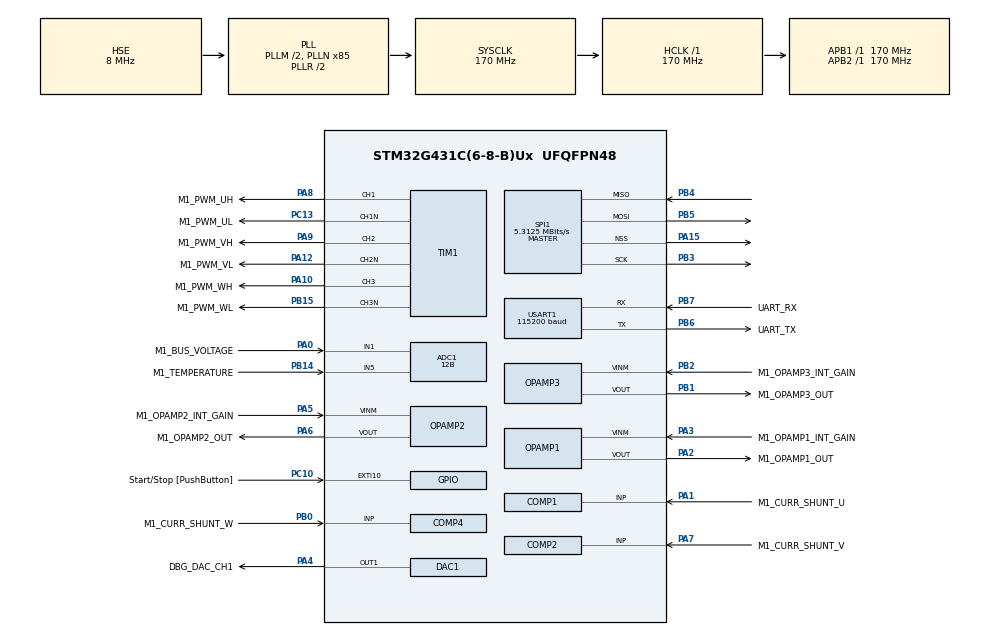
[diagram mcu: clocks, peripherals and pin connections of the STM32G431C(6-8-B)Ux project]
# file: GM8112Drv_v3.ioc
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MotorControl.BEMF_CONSISTENCY_TOL=64
MotorControl.R_BRAKE_SWITCH_OFF_THRES_V=22
MotorControl.PID_FLUX_KI_DEFAULT=3865
MotorControl.LOW_SIDE_BRAKE_STATE=false
ADC1.LowPowerAutoWait=DISABLE
MotorControl.PHASE_VL_GPIO_PORT=GPIOA
MotorControl.IPs=CORDIC,NVIC,RCC,SYS,MotorControl,TIM1,COMP1,COMP2,COMP4,OPAMP1,OPAMP2,OPAMP3,ADC1,ADC2,TIM2,DAC1,USART1
MotorControl.OCP_OUTPUT_MODE=INT_MODE
PC10.GPIO_PuPd=GPIO_NOPULL
ADC1.InjectedOffsetNumber-2\#ChannelInjectedConversion=ADC_OFFSET_NONE
MotorControl.PHASE_VH_POLARITY=H_ACTIVE_HIGH
MotorControl.THREE_SHUNT_INDEPENDENT_RESOURCES=true
MotorControl.PHASE_WL_GPIO_PIN=LL_GPIO_PIN_15
PA10.GPIO_PuPd=GPIO_PULLDOWN
MotorControl.ENCODER_PPR=400
ADC2.InjectedChannel-2\#ChannelInjectedConversion=ADC_CHANNEL_VOPAMP3_ADC2
MotorControl.OV_VOLTAGE_PROT_ENABLING=true
MotorControl.OPEN_LOOP_SPEED_RAMP_DURATION_MS=1000
MotorControl.OCPB_OUTPUT_GPIO_PORT=GPIOA
MotorControl.ANGC={0,0,0,0,0,0,0,0}
MotorControl.SINGLEDRIVE=true
MotorControl.HFI_HP_ID_1_COEFF=-1.741737
MotorControl.USART_REMAPPING=NO_REMAP_USART1
MotorControl.EMERGENCY_STOP_GPIO_PORT=GPIOA
MotorControl.OCPC_OUTPUT_MODE=INT_MODE
MotorControl.OPEN_LOOP_VOLTAGE_d=6000
COMP2.Output=COMP_OUTPUT_TIM1BKIN2
MotorControl.OCPB_OUTPUT_MODE=INT_MODE
MotorControl.OCPA_OUTPUT_MODE=INT_MODE
MotorControl.OCPC_INVERTINGINPUT_MODE=INT_MODE
MotorControl.HFI_LP_ID_1_COEFF=0.052094
MotorControl.OVP_FILTER=COMP_Mode_HighSpeed
MotorControl.DEFAULT_DAC_MOTOR=0
MotorControl.TF_KDDIV=8192
MotorControl.H3_GPIO_PORT=GPIOB
TIM1.Pulse-PWM\ Generation5\ No\ Output=(((PWM_PERIOD_CYCLES) / 2) + 1)
SPI1.Direction=SPI_DIRECTION_2LINES
RCC.APB2TimFreq_Value=170000000
MotorControl.HFI_DC_2_COEFF=0.00146
PB6.Signal=USART1_TX
SPI1.CalculateBaudRate=5.3125 MBits/s
MotorControl.HFI_NOTCH_IQD_4_COEFF=-0.871066
MotorControl.OCP_NONINVERTINGINPUT_GPIO_PIN=LL_GPIO_PIN_7
ADC2.EOCSelection=ADC_EOC_SINGLE_CONV
MotorControl.FINAL_I_ALIGNMENT=816
MotorControl.OVP_OUTPUT_GPIO_PIN=LL_GPIO_PIN_2
MotorControl.ENCODER_AVAILABLE=true
MotorControl.OPAMP1_INVERTINGINPUT_GPIO_PORT=GPIOA
NVIC.EXTI15_10_IRQn=true\:3\:0\:false\:true\:false\:6\:true\:true
MotorControl.HFI_RESTARTTIMESEC=0.1
OPAMP2.PgaGain=OPAMP_PGA_GAIN_16_OR_MINUS_15
MotorControl.HALL_ICx_FILTER=221
PB3.Mode=Full_Duplex_Master
ADC1.ScanConvMode=ADC_SCAN_ENABLE
MotorControl.ENC_MEAS_ERRORS_BEFORE_FAULTS=3
TIM1.LockLevel=TIM_LOCKLEVEL_1
MotorControl.HFI_WAITTRACK=20
MotorControl.OPAMP3_NONINVERTINGINPUT_PHB_GPIO_PORT=GPIOB
RCC.ADC12Freq_Value=42500000
MotorControl.ADC_AHBPERIPH=RCC_AHBPeriph_ADC12
TIM1.Break2Polarity=TIM_BREAK2POLARITY_HIGH
MotorControl.PID_TORQUE_KI_DEFAULT=3865
PB14.Mode=IN5-Single-Ended
MotorControl.H2_GPIO_PIN=LL_GPIO_PIN_7
PB1.GPIO_Label=M1_OPAMP3_OUT
TIM1.DeadTime=((DEAD_TIME_COUNTS) / 2)
MotorControl.DAC_TIMER_CH1_GPIO_PIN=LL_GPIO_PIN_4
SPI1.DataSize=SPI_DATASIZE_16BIT
TIM1.OCMode_PWM-PWM\ Generation1\ CH1\ CH1N=TIM_OCMODE_PWM1
MotorControl.AMPLIFICATION_GAIN=9.14
MotorControl.PWBDID=10015
PA8.Signal=S_TIM1_CH1
ADC1.InjectedConvMode=None
MotorControl.PWM_TIMER_REMAPPING=PWM_PARTIAL_REMAP
MotorControl.HFI_WAITSYNCH=20
PA0.Signal=ADC1_IN1
MotorControl.OPAMP3_NONINVERTINGINPUT_PHC_GPIO_PIN=LL_GPIO_PIN_0
MotorControl.OCPB_SELECTION=COMP2
ExtraMW.MotorControl.Template=templates
MotorControl.CORD_MEAS_ERRORS_BEFORE_FAULTS=3
MotorControl.OV_TEMPERATURE_THRESHOLD_C=110
Mcu.Package=UFQFPN48
PB1.Signal=SharedAnalog_PB1
ADC1.InjectedChannel-2\#ChannelInjectedConversion=ADC_CHANNEL_12
MotorControl.OCPB_INVERTINGINPUT_MODE=INT_MODE
MotorControl.OPAMP2_NONINVERTINGINPUT_PHC_GPIO_PIN=LL_GPIO_PIN_7
TIM1.OCMode_PWM-PWM\ Generation3\ CH3\ CH3N=TIM_OCMODE_PWM1
PA10.Signal=S_TIM1_CH3
MotorControl.HIGH_SIDE_BRAKE_STATE=false
MotorControl.DRIVES_NUMBER_SELECTION=SINGLEDRIVE
VP_COMP2_VS_VREFINT14.Mode=VREFINT_14
MotorControl.USART_SELECTION=USE_USART1
MotorControl.OPAMP2_SELECTION=OPAMP2
MotorControl.PHASE4_DURATION=3484
RCC.APB1TimFreq_Value=170000000
ADC1.InjectedOffsetNumber-1\#ChannelInjectedConversion=ADC_OFFSET_NONE
MotorControl.HFI_SPD_BUFFER_DEPTH_01HZ=64
ADC2.ExternalTrigInjecConvEdge=ADC_EXTERNALTRIGINJECCONV_EDGE_RISING
MotorControl.USE_3OPAMPS=true
MotorControl.OPAMP_INVERTINGINPUT=OPAMP1_InvertingInput_PA3
ADC1.InjectedChannel-1\#ChannelInjectedConversion=ADC_CHANNEL_3
MotorControl.VARIANCE_THRESHOLD=0.1
ADC2.EnableAnalogWatchDog1=false
MotorControl.SPD_DIFFERENTIAL_TERM_ENABLING=false
ADC2.EnableAnalogWatchDog2=false
PA4.GPIO_Label=DBG_DAC_CH1
PA8.GPIO_Speed=GPIO_SPEED_FREQ_HIGH
ADC1.EOCSelection=ADC_EOC_SINGLE_CONV
ADC2.EnableAnalogWatchDog3=false
MotorControl.PID_SPEED_KI_DEFAULT=2693
MotorControl.SP_KIDIV=8192
PF1-OSC_OUT.Signal=RCC_OSC_OUT
RCC.HSI48_VALUE=48000000
ADC2.ScanConvMode=ADC_SCAN_ENABLE
MotorControl.OPAMP1_OUT_GPIO_PORT=GPIOA
PA5.Mode=PGA Connected-INVERTINGINPUT_IO0_BIAS
MotorControl.HFI_NS_MIN_SAT_DIFF=0
MotorControl.HFI_IDH_DELAY=32400
MotorControl.PHASE_W_GPIO_PORT=GPIOB
MotorControl.BKIN_MODE=NONE
MotorControl.OVP_INVERTINGINPUT_GPIO_PORT=GPIOA
MotorControl.PHASE_CURRENTS_GPIO_PIN=LL_GPIO_PIN_0
TIM1.CounterMode=TIM_COUNTERMODE_CENTERALIGNED1
PC13.Signal=TIM1_CH1N
MotorControl.WB_to_Mx_version=1.1.0
PB6.GPIO_PuPd=GPIO_NOPULL
MotorControl.TEMP_FDBK_ADC=ADC1
MotorControl.OPEN_LOOP_SPEED_RPM=100
MotorControl.CORD_FIFO_DEPTH_01HZ=64
MotorControl.REGULATION_EXECUTION_RATE=1
MotorControl.INRUSH_CURRLIMIT_CHANGE_AFTER_MS=1000
MotorControl.OPAMP2_NONINVERTINGINPUT_PHC_GPIO_PORT=GPIOA
MotorControl.BKIN2_FILTER=3
PA3.Mode=PGA Connected-INVERTINGINPUT_IO0_BIAS
TIM1.AutoReloadPreload=TIM_AUTORELOAD_PRELOAD_DISABLE
MotorControl.HFI_DC_3_COEFF=1.889033
MotorControl.PHASE_CURRENTS_CHANNEL=ADC_CHANNEL_9
TIM1.Channel-PWM\ Generation2\ CH2\ CH2N=TIM_CHANNEL_2
PA8.GPIO_Label=M1_PWM_UH
MotorControl.HIGH_SIDE_IDLE_STATE=false
SH.SharedAnalog_PA7.1=OPAMP2_VINP,PGA Connected-INVERTINGINPUT_IO0_BIAS
MotorControl.HFI_FREQUENCY=400
MotorControl.SP_KPDIV=1024
MotorControl.OCPA_INVERTINGINPUT_GPIO_PORT=GPIOA
SH.COMP_DAC11_group.0=DAC1_OUT1,DAC_OUT1
MotorControl.OPAMP2_NONINVERTINGINPUT_PHB_GPIO_PORT=GPIOA
MotorControl.OVP_SELECTION=COMP2
SH.SharedAnalog_PA7.0=COMP2_INP,INP
MotorControl.CTRBDID=10015
MotorControl.POSITION_CTRL_KD_GAIN=1000
MotorControl.PHASE_UH_GPIO_PIN=LL_GPIO_PIN_8
MotorControl.BKIN2_MODE=INT_MODE
PB14.Signal=ADC1_IN5
PA5.Signal=OPAMP2_VINM
MotorControl.INRUSH_CURRLIMIT_GPIO_PIN=LL_GPIO_PIN_4
MotorControl.NOMINAL_BUS_VOLTAGE_V=22
NVIC.TIM1_BRK_TIM15_IRQn=true\:4\:1\:true\:true\:false\:1\:true\:true
MotorControl.HFI_NOTCH_IQD_0_COEFF=0.935533
MotorControl.OCPC_OUTPUT_GPIO_PIN=LL_GPIO_PIN_1
MotorControl.DEBUG_DAC_CH2=false
MotorControl.DEBUG_DAC_CH1=true
MotorControl.LCD_MODE=LCD_FULL
TIM1.TIM_MasterOutputTrigger=TIM_TRGO_OC4REF
VP_COMP4_VS_VREFINT14.Mode=VREFINT_14
MotorControl.OCPC_NONINVERTINGINPUT=COMP4_NonInvertingInput_PB0
PB15.GPIO_Label=M1_PWM_WL
SPI1.Mode=SPI_MODE_MASTER
PA1.GPIO_Label=M1_CURR_SHUNT_U
MotorControl.OPAMP_NONINVERTINGINPUT_GPIO_PIN=LL_GPIO_PIN_7
MotorControl.OCP_INVERTINGINPUT_GPIO_PORT=GPIOA
MotorControl.PHASE4_FINAL_SPEED_RPM=120
TIM1.Channel-PWM\ Generation4\ No\ Output=TIM_CHANNEL_4
MotorControl.OCPC_INVERTINGINPUT_GPIO_PIN=LL_GPIO_PIN_4
MotorControl.OPAMP_OUT_GPIO_PORT=GPIOA
ADC2.Resolution=ADC_RESOLUTION_12B
MotorControl.PHASE1_FINAL_SPEED_RPM=0
MotorControl.OCP_OUTPUTPOL=COMP_OutputPol_NonInverted
MotorControl.OCPB_OUTPUT=COMP_Output_TIM1BKIN2
MotorControl.HFI_NOTCH_IQD_3_COEFF=1.798584
ADC1.ExternalTrigConv=ADC_SOFTWARE_START
MotorControl.HFI_AMPLITUDE=25
ADC1.master=1
PA5.GPIO_Label=M1_OPAMP2_INT_GAIN
MotorControl.START_STOP_POLARITY_EDGE=GPIO_NOPULL
RCC.ADC12CLockSelection=RCC_ADC12CLKSOURCE_PLL
MotorControl.POSITION_CTRL_KDDIV=16
MotorControl.OCP_OUTPUT_GPIO_AF=GPIO_AF_2
MotorControl.OFST={0,0,0,0,0,0,0,0}
ProjectManager.HeapSize=0x200
ADC2.InjectedChannel-1\#ChannelInjectedConversion=ADC_CHANNEL_3
OPAMP1.SelfCalibration=Disable
MotorControl.START_STOP_BTN=true
NVIC.PriorityGroup=NVIC_PRIORITYGROUP_3
TIM1.SourceBRK2DigInput=TIM_BREAKINPUTSOURCE_DISABLE
VP_MotorControl_MC_ENABLED.Mode=Enabled
MotorControl.SW_OV_CURRENT_PROT_ENABLING=true
MotorControl.OCPB_INVERTINGINPUT=COMPX_InvertingInput_VREF_1_4
MotorControl.UD_VOLTAGE_THRESHOLD_V=8
Mcu.Family=STM32G4
MotorControl.PHASE3_FINAL_CURRENT=816
MotorControl.PHASE2_FINAL_SPEED_RPM=120
MotorControl.USART_RX_GPIO_PORT=GPIOB
MotorControl.HFI_DC_1_COEFF=0.002921
MotorControl.EMERGENCY2_STOP_GPIO_PORT=GPIOA
MotorControl.EMERGENCY2_STOP_GPIO_PIN=LL_GPIO_PIN_11
MotorControl.OPAMP3_INVERTINGINPUT_GPIO_PIN=LL_GPIO_PIN_2
ADC1.Overrun=ADC_OVR_DATA_PRESERVED
MotorControl.OCPB_INVERTINGINPUT_GPIO_PORT=GPIOA
ADC1.ContinuousConvMode=DISABLE
MotorControl.OPEN_LOOP_VF=false
USART1.BaudRate=115200
MotorControl.RTOS=NONE
MotorControl.PHASE_V_GPIO_PIN=LL_GPIO_PIN_6
PA0.GPIO_Label=M1_BUS_VOLTAGE
MotorControl.PHASE_VL_GPIO_PIN=LL_GPIO_PIN_12
MotorControl.HW_OV_CURRENT_PROT_BYPASS=false
MotorControl.H2_GPIO_PORT=GPIOB
MotorControl.PHASE_WH_POLARITY=H_ACTIVE_HIGH
TIM1.Pulse-PWM\ Generation1\ CH1=((PWM_PERIOD_CYCLES) / 4)
MotorControl.OVP_NONINVERTINGINPUT=COMP2_NonInvertingInput_PA7
MotorControl.OVP_OUTPUT_GPIO_AF=GPIO_AF_2
PB15.Signal=TIM1_CH3N
ADC2.DiscontinuousConvMode=DISABLE
MotorControl.DEFAULT_FLUX_COMPONENT=0
MotorControl.OCP_NONINVERTINGINPUT=COMP2_NonInvertingInput_PA7
MotorControl.OVERCURR_FEEDBACK_POLARITY=EMSTOP_ACTIVE_LOW
MotorControl.LOW_SIDE_IDLE_STATE=false
MotorControl.OCPC_OUTPUT_GPIO_AF=GPIO_AF_2
MotorControl.MAX_APPLICATION_SPEED=300
MotorControl.HFI_LP_ID_0_COEFF=0.026047
MotorControl.PHASE_UH_POLARITY=H_ACTIVE_HIGH
MotorControl.OCPC_SELECTION=COMP4
TIM1.Prescaler=((TIM_CLOCK_DIVIDER) - 1)
MotorControl.OCPC_OUTPUT_GPIO_PORT=GPIOB
MotorControl.VBUS_PARTITIONING_FACTOR=0.0963
MotorControl.OCPC_NONINVERTINGINPUT_GPIO_PORT=GPIOB
ADC1.Resolution=ADC_RESOLUTION_12B
MotorControl.OCPA_INVERTINGINPUT=COMPX_InvertingInput_VREF_1_4
ADC2.InjectedRank-1\#ChannelInjectedConversion=1
RCC.HSE_VALUE=8000000
MotorControl.OPAMP2_INVERTINGINPUT_GPIO_PORT=GPIOA
ADC2.master=1
ADC2.InjectedRank-2\#ChannelInjectedConversion=2
MotorControl.FEED_FORWARD_CURRENT_REG_ENABLING=false
MotorControl.PID_SPEED_KD_DEFAULT=0
PC10.GPIO_ModeDefaultEXTI=GPIO_MODE_IT_FALLING
MotorControl.HFI_LOCKFREQ=73
MotorControl.OCPA_SELECTION=COMP1
MotorControl.HFI_LP_ID_2_COEFF=0.026047
PA14.Mode=Serial_Wire
PB5.Mode=Full_Duplex_Master
MotorControl.OCPA_OUTPUT_GPIO_AF=GPIO_AF_2
VP_ADC2_OPAMP_INTERNAL3.Mode=IN-OPAMP3
PC13.GPIO_PuPd=GPIO_PULLDOWN
VP_SYS_VS_DBSignals.Mode=DisableDeadBatterySignals
MotorControl.OVP_OUTPUT_GPIO_PORT=GPIOA
PB7.Signal=USART1_RX
MotorControl.HALL_MEAS_ERRORS_BEFORE_FAULTS=3
MotorControl.OPAMP3_NONINVERTINGINPUT_PHC_GPIO_PORT=GPIOB
MotorControl.FW_VOLTAGE_REF=985
MotorControl.PID_FLUX_KD_DEFAULT=100
MotorControl.HFI_PID_KP_DEFAULT=800
MotorControl.VBUS_CHANNEL=ADC_CHANNEL_1
MotorControl.SERIAL_COM_MODE=COM_BIDIRECTIONAL
PB7.GPIO_Label=UART_RX
ADC2.InjectedSamplingTime-1\#ChannelInjectedConversion=ADC_SAMPLETIME_6CYCLES_5
MotorControl.OPAMP1_NONINVERTINGINPUT_PHB=OPAMP1_NonInvertingInput_PA1
MotorControl.PHASE_V_CURR_ADC=ADC2
PA6.Signal=SharedAnalog_PA6
MotorControl.OPAMP1_NONINVERTINGINPUT_PHA=OPAMP1_NonInvertingInput_PA1
MotorControl.PHASE_VH_GPIO_PIN=LL_GPIO_PIN_9
PB15.GPIO_PuPd=GPIO_PULLDOWN
TIM1.Pulse-PWM\ Generation2\ CH2=((PWM_PERIOD_CYCLES) / 4)
MotorControl.R_BRAKE_GPIO_PIN=LL_GPIO_PIN_5
MotorControl.OCPB_OUTPUT_GPIO_AF=GPIO_AF_2
MotorControl.HFI_NSDETPOINTSSKIP=10
PA15.Signal=SPI1_NSS
MotorControl.OPAMP_NONINVERTINGINPUT=OPAMP1_NonInvertingInput_PA7
MotorControl.PLL_KI_GAIN=29
PA10.GPIO_Speed=GPIO_SPEED_FREQ_HIGH
MotorControl.POLE_PAIR_NUM=21
MotorControl.PHASE1_FINAL_CURRENT=816
MotorControl.OPAMP2_OUT_GPIO_PORT=GPIOA
MotorControl.SP_KDDIV=16
TIM1.BreakState=TIM_BREAK_DISABLE
MotorControl.PHASE_V_CURR_CHANNEL=ADC_CHANNEL_3
MotorControl.HFI_HIFRAMPLSCAN=25
MotorControl.HFI_MAXANGLEDIFF=3640
MotorControl.SW_DEADTIME_NS=800
MotorControl.FW_KPDIV=32768
MotorControl.OCPA_INVERTINGINPUT_MODE=INT_MODE
ADC1.InjectedSamplingTime-1\#ChannelInjectedConversion=ADC_SAMPLETIME_6CYCLES_5
PF1-OSC_OUT.Mode=HSE-External-Oscillator
MotorControl.CUBE_MX_VER=5.6.1
MotorControl.SPEED_BAND_LOWER_LIMIT=15
PA12.GPIO_Speed=GPIO_SPEED_FREQ_HIGH
MotorControl.PWM_TIMER_SELECTION=PWM_TIM1
MotorControl.R_BRAKE_GPIO_PORT=GPIOD
PB4.Signal=SPI1_MISO
MotorControl.OVP_OUTPUT=COMP_Output_TIM1BKIN
PA3.Signal=OPAMP1_VINM
MotorControl.OCP_NONINVERTINGINPUT_GPIO_PORT=GPIOA
TIM1.SourceBRK2COMP2Polarity=TIM_BREAKINPUTSOURCE_POLARITY_HIGH
MotorControl.CLOCK_FREQUENCY=CPU_CLK_170_MHZ
MotorControl.POSITION_LOOP_FREQUENCY_HZ=1000
MotorControl.EXT_CLOCK_FREQUENCY=EXT_CLK_8_MHZ
MotorControl.PHASE_U_GPIO_PIN=LL_GPIO_PIN_2
TIM1.OCMode_PWM-PWM\ Generation4\ No\ Output=TIM_OCMODE_PWM2
MotorControl.HFI_MINIMUM_SPEED_RPM=402
ADC2.ExternalTrigInjecConv=ADC_EXTERNALTRIGINJEC_T1_CC4
TIM1.OffStateIDLEMode=TIM_OSSI_ENABLE
MotorControl.STO_FIFO_DEPTH_DPP=64
MotorControl.TRANSITION_DURATION=25
MotorControl.STO_FIFO_DEPTH_01HZ=64
MotorControl.OV_CURR_BYPASS_GPIO_PIN=LL_GPIO_PIN_5
MotorControl.CORD_VARIANCE_THRESHOLD=4
MotorControl.HFI_STEPANGLE=3640
MotorControl.OCP_OUTPUT_GPIO_PIN=LL_GPIO_PIN_2
MotorControl.HFI_LP_ID_4_COEFF=-0.598595
MotorControl.PHASE1_DURATION=1000
MotorControl.ENC_ICx_FILTER=128
ADC2.EnableRegularConversion=DISABLE
MotorControl.STO_HFI_RPM_TH=460
PA9.GPIO_PuPd=GPIO_PULLDOWN
PA12.GPIO_Label=M1_PWM_VL
MotorControl.PHASE_UL_GPIO_AF=GPIO_AF_4
MotorControl.GAIN1=-20371
MotorControl.GAIN2=17965
USART1.VirtualMode-Asynchronous=VM_ASYNC
PA13.Signal=SYS_JTMS-SWDIO
TIM1.Pulse-PWM\ Generation3\ CH3=((PWM_PERIOD_CYCLES) / 4)
VP_COMP1_VS_VREFINT14.Mode=VREFINT_14
SH.S_TIM1_CH1.0=TIM1_CH1,PWM Generation1 CH1 CH1N
MotorControl.PHASE5_FINAL_CURRENT=816
MotorControl.OCPA_NONINVERTINGINPUT=COMP1_NonInvertingInput_PA1
MotorControl.ENC_INVERT_SPEED=false
MotorControl.DEFAULT_CONTROL_MODE=STC_SPEED_MODE
ADC1.EnableAnalogWatchDog3=false
ADC1.EnableAnalogWatchDog2=false
ADC1.EnableAnalogWatchDog1=false
RCC.USBFreq_Value=170000000
MotorControl.PLL_KP_GAIN=372
PA1.Signal=SharedAnalog_PA1
MotorControl.OBS_MINIMUM_SPEED_RPM=90
MotorControl.HFI_NSMAXDETPOINTS=20
MotorControl.PHASE3_FINAL_SPEED_RPM=120
ExtraMW.MotorControl.Config=MotorControl
MotorControl.DAC_EMULATED=false
MotorControl.HFI_PLL_KI_DEFAULT=0.00400
MotorControl.OPAMP2_INVERTINGINPUT=OPAMP2_InvertingInput_PA5
board=custom
MotorControl.MIN_APPLICATION_SPEED=0
RCC.VCOOutputFreq_Value=340000000
MotorControl.EMERGENCY_STOP_GPIO_PIN=LL_GPIO_PIN_11
MotorControl.PHASE_VH_GPIO_PORT=GPIOA
PB15.Mode=PWM Generation3 CH3 CH3N
VP_TIM1_VS_no_output4.Mode=PWM Generation4 No Output
ADC2.DataAlign=ADC_DATAALIGN_LEFT
MotorControl.HFI_PID_KI_DEFAULT=400
MotorControl.OPAMP3_NONINVERTINGINPUT_PHC=OPAMP3_NonInvertingInput_PB0
MotorControl.OPAMP3_NONINVERTINGINPUT_PHA=OPAMP3_NonInvertingInput_PB0
MotorControl.OPAMP_NONINVERTINGINPUT_GPIO_PORT=GPIOA
MotorControl.OPAMP3_NONINVERTINGINPUT_PHB=OPAMP3_NonInvertingInput_PB0
MotorControl.TEMPERATURE_READING=true
MotorControl.ALIGNMENT_DURATION=700
MotorControl.OPAMP_PGAGAIN=OPAMP_OPAMP_PGAGain_16
TIM1.OffStateRunMode=TIM_OSSR_ENABLE
MotorControl.OPAMP3_NONINVERTINGINPUT_PHA_GPIO_PORT=GPIOB
TIM1.BreakPolarity=TIM_BREAKPOLARITY_HIGH
MotorControl.BRKIN2_GPIO_AF=GPIO_AF_12
MotorControl.OVP_OUTPUT_MODE=INT_MODE
ADC1.NbrOfConversion=2
PC13.Mode=PWM Generation1 CH1 CH1N
ADC1.OffsetNumber-2\#ChannelRegularConversion=ADC_OFFSET_NONE
MotorControl.CCMRAM_ENABLED=false
MotorControl.POSITION_CTRL_KIDIV=32768
ADC2.EnableInjectedConversion=ENABLE
RCC.SYSCLKFreq_VALUE=170000000
MotorControl.SPEED_SENSOR_SELECTION=ENCODER
MotorControl.OCP_INVERTINGINPUT_MODE=INT_MODE
TIM1.Break2Filter=3
MotorControl.OPAMP2_INVERTINGINPUT_GPIO_PIN=LL_GPIO_PIN_5
MotorControl.HALL_TIMER_SELECTION=HALL_TIM4
PB2.Mode=PGA Connected-INVERTINGINPUT_IO0_BIAS
PB2.GPIO_Label=M1_OPAMP3_INT_GAIN
SH.S_TIM1_CH3.0=TIM1_CH3,PWM Generation3 CH3 CH3N
RCC.HSI_VALUE=16000000
PA8.GPIO_PuPd=GPIO_PULLDOWN
SH.SharedAnalog_PA1.1=OPAMP1_VINP,PGA Connected-INVERTINGINPUT_IO0_BIAS
NVIC.TIM1_UP_TIM16_IRQn=true\:0\:0\:false\:true\:false\:2\:true\:true
RCC.PLLP=RCC_PLLP_DIV8
MotorControl.PID_SPEED_KP_DEFAULT=2026
MotorControl.MCU_TYPE=STM32G431CB
SH.SharedAnalog_PA1.0=COMP1_INP,INP
MotorControl.OVP_INVERTINGINPUT=COMPX_InvertingInput_VREF
RCC.PLLM=RCC_PLLM_DIV2
RCC.PLLN=85
MotorControl.OPAMP_INVERTINGINPUT_GPIO_PIN=LL_GPIO_PIN_3
PA9.GPIO_Speed=GPIO_SPEED_FREQ_HIGH
MotorControl.OPAMP3_INVERTINGINPUT=OPAMP3_InvertingInput_PB2
MotorControl.OPAMP1_INVERTINGINPUT_MODE=EXT_MODE
ADC1.DataAlign=ADC_DATAALIGN_LEFT
MotorControl.DAC_TIMER_SELECTION=TIM3
ADC2.InjNumberOfConversion=2
PA3.GPIO_Label=M1_OPAMP1_INT_GAIN
MotorControl.PHASE_VH_GPIO_AF=GPIO_AF_6
MotorControl.ID_DEMAG=-816
MotorControl.ENCODER=true
MotorControl.H3_GPIO_PIN=LL_GPIO_PIN_8
MotorControl.HFI_PLL_KP_DEFAULT=0.00060
NVIC.ADC1_2_IRQn=true\:2\:0\:true\:true\:false\:3\:true\:true
MotorControl.ENC_TIMER_REMAPPING=NO_REMAP_TIM2
MotorControl.H1_GPIO_PORT=GPIOB
TIM1.OCIdleState_1=TIM_OCIDLESTATE_RESET
TIM1.OCIdleState_2=TIM_OCIDLESTATE_RESET
DAC1.DAC_OutputBuffer=DAC_OUTPUTBUFFER_DISABLE
SPI1.VirtualType=VM_MASTER
MotorControl.ADC_REFERENCE_VOLTAGE=3.30
TIM1.OCFastMode_PWM=TIM_OCFAST_DISABLE
TIM1.OCIdleState_5=TIM_OCIDLESTATE_RESET
TIM1.Break2State=TIM_BREAK2_ENABLE
TIM1.OCIdleState_6=TIM_OCIDLESTATE_RESET
TIM1.OCIdleState_3=TIM_OCIDLESTATE_RESET
TIM1.OCIdleState_4=TIM_OCIDLESTATE_RESET
PB14.GPIO_Label=M1_TEMPERATURE
USART1.WordLength=WORDLENGTH_8B
PA14.GPIO_Label=TCK
MotorControl.CORD_F1=16384
MotorControl.CORD_F2=1024
MotorControl.CORD_MAX_ACCEL_DPPP=999
MotorControl.HFI_RESTART_RPM_TH=(((HFI_STO_RPM_TH)+(STO_HFI_RPM_TH))/2)
MotorControl.SPEED_BAND_UPPER_LIMIT=17
ADC2.InjectedOffset-1\#ChannelInjectedConversion=0
PA6.GPIO_Label=M1_OPAMP2_OUT
PB6.GPIO_Label=UART_TX
MotorControl.CLOCK_SOURCE=EXTERNAL
MotorControl.OPAMP2_NONINVERTINGINPUT_PHB_GPIO_PIN=LL_GPIO_PIN_7
MotorControl.USART_SPEED=115200
MotorControl.OCPB_OUTPUT_GPIO_PIN=LL_GPIO_PIN_2
RCC.SYSCLKSource=RCC_SYSCLKSOURCE_PLLCLK
MotorControl.OPAMP1_NONINVERTINGINPUT_PHB_GPIO_PIN=LL_GPIO_PIN_1
ExtraMW.MotorControl.Mode=MotorControl
MotorControl.FLUX_WEAKENING_ENABLING=false
MotorControl.MTPA_ENABLING=false
MotorControl.BOARD=CUSTOM
TIM1.TIM_SlaveMode=TIM_SLAVEMODE_TRIGGER
MotorControl.OCP_FILTER=COMP_Mode_HighSpeed
MotorControl.FW_KIDIV=32768
PB7.GPIO_Mode=GPIO_MODE_AF_PP
MotorControl.PID_TORQUE_KP_DEFAULT=2823
MotorControl.PHASE5_DURATION=3484
MotorControl.OV_CURR_BYPASS_GPIO_PORT=GPIOD
MotorControl.OCPC_NONINVERTINGINPUT_GPIO_PIN=LL_GPIO_PIN_0
MotorControl.ENC_A_GPIO_PORT=GPIOA
MotorControl.ADC_CLOCK_WB_FREQ=68
ADC1.Channel-2\#ChannelRegularConversion=ADC_CHANNEL_5
ADC1.InjNumberOfConversion=2
TIM1.AutomaticOutput=TIM_AUTOMATICOUTPUT_DISABLE
PB6.Mode=Asynchronous
MotorControl.POSITION_CTRL_KPDIV=1024
TIM1.SourceBRK2COMP4Polarity=TIM_BREAKINPUTSOURCE_POLARITY_HIGH
PB2.Signal=OPAMP3_VINM
MotorControl.NOMINAL_CURRENT=816
MotorControl.PHASE_WH_GPIO_AF=GPIO_AF_6
MotorControl.OPAMP1_INVERTINGINPUT=OPAMP1_InvertingInput_PA3
MotorControl.INTERNAL_OVERVOLTAGEPROTECTION=false
MotorControl.RS=2.07
MotorControl.PHASE_U_CURR_ADC=ADC1
MotorControl.SERIAL_COMMUNICATION=true
PA0.Mode=IN1-Single-Ended
ADC2.InjectedOffsetNumber-2\#ChannelInjectedConversion=ADC_OFFSET_NONE
MotorControl.OCPB_OUTPUTPOL=COMP_OutputPol_NonInverted
MotorControl.ENC_AVERAGING_FIFO_DEPTH=16
MotorControl.OPAMP_OUT_GPIO_PIN=LL_GPIO_PIN_2
SPI1.VirtualNSS=VM_NSSHARD
MotorControl.PHASE_WH_GPIO_PIN=LL_GPIO_PIN_10
SH.SharedAnalog_PB0.0=COMP4_INP,INP
MotorControl.PHASE_VL_POLARITY=L_ACTIVE_HIGH
MotorControl.DEFAULT_TORQUE_COMPONENT=0
MotorControl.INTERNAL_OVERCURRENTPROTECTION=true
MotorControl.OCPA_NONINVERTINGINPUT_GPIO_PORT=GPIOA
MotorControl.OCPB_NONINVERTINGINPUT=COMP2_NonInvertingInput_PA7
SH.SharedAnalog_PB0.1=OPAMP3_VINP,PGA Connected-INVERTINGINPUT_IO0_BIAS
ADC2.InjectedOffset-2\#ChannelInjectedConversion=0
ADC1.EnableInjectedConversion=ENABLE
OPAMP3.SelfCalibration=Disable
MotorControl.OPAMP_TYPE_GAIN=INTERNAL
MotorControl.CURR_SAMPLING_TIME=6
MotorControl.START_STOP_GPIO_PORT=GPIOC
MotorControl.CONSTANT1_Q=1092810
MotorControl.ADC_CLOCK_WB_DIV=4
ADC2.Overrun=ADC_OVR_DATA_PRESERVED
MotorControl.HFI_LP_ID_3_COEFF=1.494408
MotorControl.PHASE_UL_GPIO_PIN=LL_GPIO_PIN_13
MotorControl.TF_KPDIV=128
MotorControl.CONSTANT1_D=1092810
MotorControl.HFI_HP_ID_4_COEFF=-0.758482
MotorControl.HFI_DC_0_COEFF=0.00146
MotorControl.INRUSH_CURR_LIMITER_POLARITY=DOUT_ACTIVE_HIGH
MotorControl.INRUSH_CURRLIMIT_GPIO_PORT=GPIOD
TIM1.OCMode_PWM-PWM\ Generation2\ CH2\ CH2N=TIM_OCMODE_PWM1
TIM1.Period=((PWM_PERIOD_CYCLES) / 2)
NVIC.USART1_IRQn=true\:3\:1\:true\:true\:false\:5\:true\:true
PA12.GPIO_PuPd=GPIO_PULLDOWN
MotorControl.INVERTERBOARD=ESC_G4
ExtraMW=MotorControl
MotorControl.SHARED_SIGNAL_ENABLE=false
MotorControl.HFI_HP_ID_3_COEFF=1.724992
MotorControl.OCPC_OUTPUT=COMP_Output_TIM1BKIN2
MotorControl.OPAMP1_INVERTINGINPUT_GPIO_PIN=LL_GPIO_PIN_3
MotorControl.ON_OVER_VOLTAGE=TURN_OFF_PWM
MotorControl.OPAMP3_OUT_GPIO_PIN=LL_GPIO_PIN_1
MotorControl.TNOISE_NS=1000
MotorControl.FEEDBACK_NET_FILTERING=true
PB7.GPIO_PuPd=GPIO_NOPULL
MotorControl.ENABLE_SL_ALGO_FROM_PHASE=2
MotorControl.OVP_NONINVERTINGINPUT_GPIO_PIN=LL_GPIO_PIN_7
TIM1.OCPolarity_1=TIM_OCPOLARITY_HIGH
TIM1.OCPolarity_3=TIM_OCPOLARITY_HIGH
MotorControl.OPAMP1_OUT_GPIO_PIN=LL_GPIO_PIN_2
TIM1.OCPolarity_2=TIM_OCPOLARITY_HIGH
TIM1.OCPolarity_5=TIM_OCPOLARITY_HIGH
MotorControl.SEGDIV=0
TIM1.OCPolarity_4=TIM_OCPOLARITY_HIGH
MotorControl.EXT_CLK_8_MHZ=true
TIM1.OCPolarity_6=TIM_OCPOLARITY_HIGH
MotorControl.TEMP_FDBK_CHANNEL=ADC_CHANNEL_5
MotorControl.HFI_WAITAFTERNS2=4
PA9.GPIO_Label=M1_PWM_VH
MotorControl.PID_TORQUE_KD_DEFAULT=100
MotorControl.CORD_BEMF_CONSISTENCY_TOL=64
MotorControl.RSHUNT=0.00300
MotorControl.PHASE_CURRENTS_GPIO_PORT=GPIOA
MotorControl.TEMP_ADC_SAMPLING_TIME=47
MotorControl.OCP_INVERTINGINPUT=COMPX_InvertingInput_VREF_1_4
ADC2.InjectedOffsetNumber-1\#ChannelInjectedConversion=ADC_OFFSET_NONE
MotorControl.MOTOR_MAX_SPEED_RPM=300
TIM1.Channel-PWM\ Generation1\ CH1\ CH1N=TIM_CHANNEL_1
ADC1.ExternalTrigConvEdge=ADC_EXTERNALTRIGCONVEDGE_NONE
MotorControl.HFI_DC_4_COEFF=-0.894874
DAC1.DAC_Trigger_OUT1=DAC_TRIGGER_SOFTWARE
MotorControl.OPAMP_INVERTINGINPUT_MODE=EXT_MODE
MotorControl.OPAMP2_OUT_GPIO_PIN=LL_GPIO_PIN_6
TIM1.BreakFilter=0
MotorControl.MCU=STM32G431CB
ADC2.ContinuousConvMode=DISABLE
MotorControl.PID_FLUX_KP_DEFAULT=2823
MotorControl.T_MAX=110
MotorControl.BEMF_CONSISTENCY_GAIN=64
PA9.Signal=S_TIM1_CH2
MotorControl.ADC_2_PERIPH=ADC2
VP_TIM1_VS_ClockSourceITR.Mode=TriggerSource_ITR1
TIM1.Channel-PWM\ Generation3\ CH3\ CH3N=TIM_CHANNEL_3
MotorControl.ENC_TIMER_SELECTION=ENC_TIM2
ADC1.Offset-2\#ChannelRegularConversion=0
MotorControl.OCPA_OUTPUT=COMP_Output_TIM1BKIN2
MotorControl.OVP_OUTPUTPOL=COMP_OutputPol_NonInverted
MotorControl.ALIGNMENT_ANGLE_DEG=0
MotorControl.OCP_COMP_THRESHOLD=0.50
ADC2.LowPowerAutoWait=DISABLE
MotorControl.HFI_SCANROTATIONSNO=3
MotorControl.OPAMP2_INVERTINGINPUT_MODE=EXT_MODE
MotorControl.CORD_BEMF_CONSISTENCY_GAIN=64
ExtraMW.MotorControl.Root=MCSDK_v5.4.4/MotorControl
ADC1.InjectedOffset-1\#ChannelInjectedConversion=0
MotorControl.OCP_SELECTION=COMP2
MotorControl.ADC_PERIPH=ADC1
MotorControl.OVP_INVERTINGINPUT_MODE=INT_MODE
TIM1.SourceBRK2COMP1Polarity=TIM_BREAKINPUTSOURCE_POLARITY_HIGH
ADC1.DMAContinuousRequests=DISABLE
PA13.Mode=Serial_Wire
MotorControl.TEMP_FDBK_GPIO_PIN=LL_GPIO_PIN_14
MotorControl.OPAMP3_NONINVERTINGINPUT_PHB_GPIO_PIN=LL_GPIO_PIN_0
MotorControl.PHASE2_DURATION=3484
MotorControl.STM32G431CB=true
MotorControl.LDLQ_RATIO=1.000
MotorControl.HALL_SENSORS_PLACEMENT=DEGREES_120
PA4.Signal=COMP_DAC11_group
ADC1.SamplingTime-1\#ChannelRegularConversion=ADC_SAMPLETIME_47CYCLES_5
MotorControl.TRISE_NS=2000
PB5.Signal=SPI1_MOSI
MotorControl.IQMAX=816
MotorControl.HALL_PHASE_SHIFT=300
ADC1.Rank-1\#ChannelRegularConversion=1
OPAMP3.PgaGain=OPAMP_PGA_GAIN_16_OR_MINUS_15
MotorControl.HW_COMPLEMENTED_LOW_SIDE=false
MotorControl.ENC_A_GPIO_PIN=LL_GPIO_PIN_15
MotorControl.HFI_PID_KIDIV=32768
MotorControl.START_STOP_GPIO_PIN=LL_GPIO_PIN_10
MotorControl.OCP_OUTPUT_GPIO_PORT=GPIOA
MotorControl.MAX_MODULATION_INDEX=MAX_MODULATION_100_PER_CENT
TIM1.SourceBRK2COMP1=TIM_BREAKINPUTSOURCE_ENABLE
MotorControl.HFI_NOTCH_IQD_2_COEFF=0.935533
TIM1.SourceBRK2COMP2=TIM_BREAKINPUTSOURCE_ENABLE
MotorControl.PHASE_UL_GPIO_PORT=GPIOC
TIM1.SourceBRK2COMP4=TIM_BREAKINPUTSOURCE_ENABLE
ADC1.EnableRegularConversion=ENABLE
ADC1.InjectedRank-1\#ChannelInjectedConversion=1
MotorControl.MC_WORKBENCH_VERSION=5.4.4.20160
MotorControl.HFI_NOTCH_IQD_1_COEFF=-1.798584
PF0-OSC_IN.Signal=RCC_OSC_IN
PB6.GPIO_Speed=GPIO_SPEED_FREQ_LOW
MotorControl.PHASE_CURRENTS_ADC=ADC1_2
PB0.Signal=SharedAnalog_PB0
TIM1.PeriodNoDither=((PWM_PERIOD_CYCLES) / 2)
MotorControl.OPAMP_PGACONNECT=OPAMP1_PGAConnect_PA3
MotorControl.OPAMP2_NONINVERTINGINPUT_PHA_GPIO_PORT=GPIOA
MotorControl.PHASE5_FINAL_SPEED_RPM=120
MotorControl.OPAMP3_SELECTION=OPAMP3
RCC.CortexFreq_Value=170000000
MotorControl.PHASE_U_CURR_CHANNEL=ADC_CHANNEL_3
MotorControl.DISSIPATIVE_BRAKE_POLARITY=DOUT_ACTIVE_HIGH
MotorControl.HFI_REVERT_DIRECTION=true
PB6.GPIO_Mode=GPIO_MODE_AF_PP
TIM1.RepetitionCounter=(REP_COUNTER)
ADC2.InjectedConvMode=None
PC10.Signal=GPXTI10
MotorControl.ADC_1_PERIPH=ADC1
MotorControl.OPEN_LOOP_FOC=false
MotorControl.PHASE_W_CURR_ADC=ADC1
MotorControl.TF_KIDIV=512
PB0.GPIO_Label=M1_CURR_SHUNT_W
PC13.GPIO_Label=M1_PWM_UL
COMP4.Output=COMP_OUTPUT_TIM1BKIN2
MotorControl.LCD_JOYSTICK_FUNCTIONALITY=false
MotorControl.USE_INTERNAL_OPAMP=true
MotorControl.WB_to_Mx_template_version=20-04-17
ProjectManager.StackSize=0x400
MotorControl.HFI_HP_ID_0_COEFF=0.870869
MotorControl.SERIAL_COM_MOTOR=0
MotorControl.V0_V=1.055
MotorControl.OCPC_INVERTINGINPUT=COMPX_InvertingInput_VREF_1_4
MotorControl.OCPA_INVERTINGINPUT_GPIO_PIN=LL_GPIO_PIN_4
PA12.Signal=TIM1_CH2N
MotorControl.DC_CURRENT_RS_MEAS=1.50
MotorControl.PHASE_WH_GPIO_PORT=GPIOA
ADC2.DMAContinuousRequests=DISABLE
MotorControl.PHASE_UH_GPIO_AF=GPIO_AF_6
MotorControl.TEMP_FDBK_GPIO_PORT=GPIOB
RCC.HCLKFreq_Value=170000000
ADC1.Offset-1\#ChannelRegularConversion=0
MotorControl.HALL_AVERAGING_FIFO_DEPTH=6
OPAMP2.SelfCalibration=Disable
MotorControl.VBUS_GPIO_PIN=LL_GPIO_PIN_0
MotorControl.BUS_VOLTAGE_READING=true
MotorControl.OCPC_OUTPUTPOL=COMP_OutputPol_NonInverted
RCC.AHBFreq_Value=170000000
MotorControl.TFDIFFERENTIAL_TERM_ENABLING=false
MotorControl.OPEN_LOOP_K=44
ADC1.ExternalTrigInjecConv=ADC_EXTERNALTRIGINJEC_T1_CC4
MotorControl.PHASE_WL_GPIO_AF=GPIO_AF_4
MotorControl.OV_TEMPERATURE_PROT_ENABLING=true
PA15.Mode=NSS_Signal_Hard_Output
MotorControl.DEFAULT_TARGET_SPEED_RPM=120
MotorControl.OCPB_NONINVERTINGINPUT_GPIO_PORT=GPIOA
MotorControl.HFI_HP_ID_2_COEFF=0.870869
ADC1.Rank-2\#ChannelRegularConversion=2
PB4.Mode=Full_Duplex_Master
MotorControl.PHASE_UL_POLARITY=L_ACTIVE_HIGH
MotorControl.T0_C=25
MotorControl.PHASE_VL_GPIO_AF=GPIO_AF_2
VP_CORDIC_VS_CORDIC.Mode=CORDIC_Activate
PA10.GPIO_Label=M1_PWM_WH
MotorControl.OCPB_INVERTINGINPUT_GPIO_PIN=LL_GPIO_PIN_4
MotorControl.OVP_NONINVERTINGINPUT_GPIO_PORT=GPIOA
SH.SharedAnalog_PA6.0=OPAMP2_VOUT,PGA Connected-INVERTINGINPUT_IO0_BIAS
MotorControl.DEFAULT_DAC_CHANNEL_2=MC_PROTOCOL_REG_I_B
MotorControl.PHASE_W_CURR_CHANNEL=ADC_CHANNEL_12
SH.SharedAnalog_PA6.1=ADC2_IN3,IN3-Single-Ended
MotorControl.DEFAULT_DAC_CHANNEL_1=MC_PROTOCOL_REG_OBS_EL_ANGLE
MotorControl.OPAMP2_NONINVERTINGINPUT_PHA=OPAMP2_NonInvertingInput_PA7
MotorControl.LOW_SIDE_SIGNALS_ENABLING=LS_PWM_TIMER
MotorControl.OPAMP2_NONINVERTINGINPUT_PHB=OPAMP2_NonInvertingInput_PA7
MotorControl.OPAMP2_NONINVERTINGINPUT_PHC=OPAMP2_NonInvertingInput_PA7
MotorControl.ENC_B_GPIO_PIN=LL_GPIO_PIN_3
MotorControl.FW_KI_GAIN=5000
MotorControl.POSITION_CTRL_KP_GAIN=10000
MotorControl.OPAMP3_OUT_GPIO_PORT=GPIOB
OPAMP1.PgaGain=OPAMP_PGA_GAIN_16_OR_MINUS_15
MotorControl.HFI_WAITBEFORESN=6
MotorControl.OCPA_NONINVERTINGINPUT_GPIO_PIN=LL_GPIO_PIN_1
MotorControl.POSITION_CTRL_ENABLING=true
MotorControl.OCPA_OUTPUTPOL=COMP_OutputPol_NonInverted
MotorControl.PHASE4_FINAL_CURRENT=816
MotorControl.USART_TX_GPIO_PIN=LL_GPIO_PIN_6
MotorControl.OPAMP1_SELECTION=OPAMP1
MotorControl.BKIN1_FILTER=0
TIM1.Channel=TIM_CHANNEL_4
ADC2.InjectedSamplingTime-2\#ChannelInjectedConversion=ADC_SAMPLETIME_6CYCLES_5
MotorControl.OV_TEMPERATURE_HYSTERESIS_C=10
PA2.GPIO_Label=M1_OPAMP1_OUT
MotorControl.HALL_SENSORS_AVAILABLE=false
MotorControl.H1_GPIO_PIN=LL_GPIO_PIN_6
ADC1.OffsetNumber-1\#ChannelRegularConversion=ADC_OFFSET_NONE
MotorControl.OCP_OUTPUT=COMP_Output_TIM1BKIN2
PC13.GPIO_Speed=GPIO_SPEED_FREQ_HIGH
MotorControl.OCP_INVERTINGINPUT_GPIO_PIN=LL_GPIO_PIN_4
MotorControl.INRUSH_CURRLIMIT_ENABLING=false
MotorControl.ENC_USE_CH3=false
MotorControl.HALL_MTPA=false
SPI1.BaudRatePrescaler=SPI_BAUDRATEPRESCALER_32
MotorControl.MAX_MODULATION_100_PER_CENT=true
MotorControl.OCPA_OUTPUT_GPIO_PIN=LL_GPIO_PIN_0
MotorControl.ENC_B_GPIO_PORT=GPIOB
TIM1.Pulse-PWM\ Generation6\ No\ Output=(((PWM_PERIOD_CYCLES) / 2) + 1)
ADC1.InjectedSamplingTime-2\#ChannelInjectedConversion=ADC_SAMPLETIME_6CYCLES_5
MotorControl.POSITION_CTRL_KI_GAIN=1000
VP_TIM1_VS_ControllerModeTrigger.Mode=Trigger Mode
ADC1.ExternalTrigInjecConvEdge=ADC_EXTERNALTRIGINJECCONV_EDGE_RISING
MotorControl.OCPREF=5957
MotorControl.PHASE2_FINAL_CURRENT=816
PB7.GPIO_Speed=GPIO_SPEED_FREQ_LOW
ADC2.ClockPrescaler=ADC_CLOCK_ASYNC_DIV4
MotorControl.HFI_STO_RPM_TH=OBS_MINIMUM_SPEED_RPM
RCC.PLLSourceVirtual=RCC_PLLSOURCE_HSE
MotorControl.OPAMP3_INVERTINGINPUT_GPIO_PORT=GPIOB
MotorControl.MOTOR_TYPE=PMSM
MotorControl.OV_VOLTAGE_THRESHOLD_V=28
MotorControl.PWM_FREQUENCY=9000
PC10.GPIO_Label=Start/Stop [PushButton]
MotorControl.FW_KP_GAIN=3000
MotorControl.F1=16384
ADC1.DiscontinuousConvMode=DISABLE
MotorControl.F2=1024
MotorControl.OPAMP2_NONINVERTINGINPUT_PHA_GPIO_PIN=LL_GPIO_PIN_7
MotorControl.DAC_TIMER_CH1_GPIO_PORT=GPIOA
RCC.EXTERNAL_CLOCK_VALUE=12288000
MotorControl.OPAMP1_NONINVERTINGINPUT_PHB_GPIO_PORT=GPIOA
MotorControl.PHASE_V_GPIO_PORT=GPIOA
MotorControl.PHASE_UH_GPIO_PORT=GPIOA
ADC1.SamplingTime-2\#ChannelRegularConversion=ADC_SAMPLETIME_47CYCLES_5
TIM1.ClockDivision=TIM_CLOCKDIVISION_DIV2
MotorControl.CPU_CLK_170_MHZ=true
TIM1.ClearInputSource=TIM_CLEARINPUTSOURCE_NONE
MotorControl.CURRENT_READING_TOPOLOGY=THREE_SHUNT_INDEPENDENT_RESOURCES
MotorControl.INRUSH_CURRLIMIT_AT_POWER_ON=true
MotorControl.OCPC_INVERTINGINPUT_GPIO_PORT=GPIOA
MotorControl.HFI_PID_KPDIV=16384
MotorControl.UV_VOLTAGE_PROT_ENABLING=true
MotorControl.PHASE_U_GPIO_PORT=GPIOA
ProjectManager.TargetToolchain=MDK-ARM V5
MotorControl.DAC_TIMER_CH2_GPIO_PORT=GPIOA
MotorControl.OPAMP3_NONINVERTINGINPUT_PHA_GPIO_PIN=LL_GPIO_PIN_0
MotorControl.PHASE_WL_POLARITY=L_ACTIVE_HIGH
MotorControl.NB_CONSECUTIVE_TESTS=2
MotorControl.OVPREF=23830
MotorControl.OVERCURR_PROTECTION_HW_DISABLING=DOUT_ACTIVE_HIGH
ADC1.InjectedOffset-2\#ChannelInjectedConversion=0
MotorControl.VBUS_GPIO_PORT=GPIOA
ADC1.Channel-1\#ChannelRegularConversion=ADC_CHANNEL_1
MotorControl.CONSTANT2_QD=55311
MotorControl.OCPB_NONINVERTINGINPUT_GPIO_PIN=LL_GPIO_PIN_7
MotorControl.USART_TX_GPIO_PORT=GPIOB
MotorControl.VBUS_ADC=ADC1
MotorControl.MEAS_ERRORS_BEFORE_FAULTS=3
RCC.LSE_VALUE=32768
MotorControl.OBS_MEAS_ERRORS_BEFORE_FAULTS=3
PF0-OSC_IN.Mode=HSE-External-Oscillator
MotorControl.MOTOR_VOLTAGE_CONSTANT=44.1
SH.SharedAnalog_PB1.0=OPAMP3_VOUT,PGA Connected-INVERTINGINPUT_IO0_BIAS
SH.SharedAnalog_PB1.1=ADC1_IN12,IN12-Single-Ended
MotorControl.OPAMP_INVERTINGINPUT_GPIO_PORT=GPIOA
TIM1.OCNPolarity_1=TIM_OCNPOLARITY_HIGH
MotorControl.REGCONVADC=ADC1
TIM1.OCNIdleState_3=TIM_OCNIDLESTATE_RESET
TIM1.OCNIdleState_2=TIM_OCNIDLESTATE_RESET
TIM1.OCNIdleState_1=TIM_OCNIDLESTATE_RESET
TIM1.Pulse-PWM\ Generation4\ No\ Output=(((PWM_PERIOD_CYCLES) / 2) - (HTMIN))
MotorControl.CORD_GAIN1=-20371
MotorControl.CORD_GAIN2=17965
MotorControl.OVP_INVERTINGINPUT_GPIO_PIN=LL_GPIO_PIN_4
RCC.APB2Freq_Value=170000000
TIM1.OCNPolarity_3=TIM_OCNPOLARITY_HIGH
TIM1.OCNPolarity_2=TIM_OCNPOLARITY_HIGH
SH.S_TIM1_CH2.0=TIM1_CH2,PWM Generation2 CH2 CH2N
PB15.GPIO_Speed=GPIO_SPEED_FREQ_HIGH
SH.SharedAnalog_PA2.0=OPAMP1_VOUT,PGA Connected-INVERTINGINPUT_IO0_BIAS
MotorControl.DAC_FUNCTIONALITY=true
MotorControl.HALL_TIMER_REMAPPING=NO_REMAP_TIM4
SH.SharedAnalog_PA2.1=ADC1_IN3,IN3-Single-Ended
MotorControl.PHASE3_DURATION=3484
MotorControl.DAC_TIMER_CH2_GPIO_PIN=LL_GPIO_PIN_0
MotorControl.START_STOP_POLARITY=DIN_ACTIVE_LOW
MotorControl.HW_DEAD_TIME_NS=500
Mcu.Name=STM32G431C(6-8-B)Ux
PA13.GPIO_Label=TMS
PA2.Signal=SharedAnalog_PA2
MotorControl.OPAMP1_NONINVERTINGINPUT_PHA_GPIO_PIN=LL_GPIO_PIN_1
MotorControl.OPAMP3_INVERTINGINPUT_MODE=EXT_MODE
MotorControl.PHASE_W_GPIO_PIN=LL_GPIO_PIN_1
PB3.Signal=SPI1_SCK
TIM1.TIM_MasterOutputTrigger2=TIM_TRGO2_RESET
PA7.GPIO_Label=M1_CURR_SHUNT_V
PA12.Mode=PWM Generation2 CH2 CH2N
MotorControl.VBUS_ADC_SAMPLING_TIME=47
MotorControl.OPAMP_SELECTION=OPAMP1
MotorControl.SERIAL_COM_CHANNEL1=MC_PROTOCOL_REG_I_A
MotorControl.SERIAL_COM_CHANNEL2=MC_PROTOCOL_REG_I_A
PB7.Mode=Asynchronous
MotorControl.USART_RX_GPIO_PIN=LL_GPIO_PIN_7
PA14.Signal=SYS_JTCK-SWCLK
MotorControl.HFI_DEBUG_MODE=false
MotorControl.OPAMP1_NONINVERTINGINPUT_PHA_GPIO_PORT=GPIOA
MotorControl.LS=0.000672
MotorControl.STARTING_ANGLE_DEG=0
ADC1.NbrOfConversionFlag=1
MotorControl.PHASE_WL_GPIO_PORT=GPIOB
MotorControl.BRKIN_GPIO_AF=GPIO_AF_2
MotorControl.OPEN_LOOP_OFF=4400
RCC.APB1Freq_Value=170000000
ADC1.ClockPrescaler=ADC_CLOCK_ASYNC_DIV4
COMP1.Output=COMP_OUTPUT_TIM1BKIN2
MotorControl.CORD_FIFO_DEPTH_DPP=64
MotorControl.OCPA_OUTPUT_GPIO_PORT=GPIOA
TIM1.TIM_MasterSlaveMode=TIM_MASTERSLAVEMODE_DISABLE
ADC1.InjectedRank-2\#ChannelInjectedConversion=2
MotorControl.dV_dT=0.023
PA7.Signal=SharedAnalog_PA7

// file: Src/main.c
/* USER CODE BEGIN Header */
/**
  ******************************************************************************
  * @file           : main.c
  * @brief          : Main program body
  ******************************************************************************
  * @attention
  *
  * <h2><center>&copy; Copyright (c) 2020 STMicroelectronics.
  * All rights reserved.</center></h2>
  *
  * This software component is licensed by ST under Ultimate Liberty license
  * SLA0044, the "License"; You may not use this file except in compliance with
  * the License. You may obtain a copy of the License at:
  *                             www.st.com/SLA0044
  *
  ******************************************************************************
  */
/* USER CODE END Header */

#include "main.h"
#include "motorcontrol.h"
#include "mc_tasks.h"

ADC_HandleTypeDef hadc1;
ADC_HandleTypeDef hadc2;

COMP_HandleTypeDef hcomp1;
COMP_HandleTypeDef hcomp2;
COMP_HandleTypeDef hcomp4;

CORDIC_HandleTypeDef hcordic;

DAC_HandleTypeDef hdac1;

OPAMP_HandleTypeDef hopamp1;
OPAMP_HandleTypeDef hopamp2;
OPAMP_HandleTypeDef hopamp3;

SPI_HandleTypeDef hspi1;

TIM_HandleTypeDef htim1;

UART_HandleTypeDef huart1;

void SystemClock_Config(void);
static void MX_GPIO_Init(void);
static void MX_ADC1_Init(void);
static void MX_ADC2_Init(void);
static void MX_COMP1_Init(void);
static void MX_COMP2_Init(void);
static void MX_COMP4_Init(void);
static void MX_CORDIC_Init(void);
static void MX_DAC1_Init(void);
static void MX_OPAMP1_Init(void);
static void MX_OPAMP2_Init(void);
static void MX_OPAMP3_Init(void);
static void MX_SPI1_Init(void);
static void MX_TIM1_Init(void);
static void MX_USART1_UART_Init(void);
static void MX_NVIC_Init(void);

int main(void)
{
  /* USER CODE BEGIN 1 */
  static MCI_Handle_t * pMCI;
  /* USER CODE END 1 */

  /* MCU Configuration--------------------------------------------------------*/

  /* Reset of all peripherals, Initializes the Flash interface and the Systick. */
  HAL_Init();

  /* Configure the system clock */
  SystemClock_Config();

  /* Initialize all configured peripherals */
  MX_GPIO_Init();
  MX_ADC1_Init();
  MX_ADC2_Init();
  MX_COMP1_Init();
  MX_COMP2_Init();
  MX_COMP4_Init();
  MX_CORDIC_Init();
  MX_DAC1_Init();
  MX_OPAMP1_Init();
  MX_OPAMP2_Init();
  MX_OPAMP3_Init();
  MX_SPI1_Init();
  MX_TIM1_Init();
  MX_USART1_UART_Init();
  MX_MotorControl_Init();

  /* Initialize interrupts */
  MX_NVIC_Init();

  /* Infinite loop */
  /* USER CODE BEGIN WHILE */
  pMCI = GetMCI(M1);
  MCI_FaultAcknowledged(pMCI);
  MC_StartMotor1();

  while(MC_GetAlignmentStatusMotor1()!= TC_ALIGNMENT_COMPLETED){}

  while(ENCODER_M1.initDone == false){};

  MC_ProgramPositionCommandMotor1((-ENCODER_M1.Offset * 2 * M_PI)/ENCODER_M1.PulseNumber, 2.0);

  while (1)
  {
    /* USER CODE END WHILE */

  }
}

void SystemClock_Config(void)
{
  RCC_OscInitTypeDef RCC_OscInitStruct = {0};
  RCC_ClkInitTypeDef RCC_ClkInitStruct = {0};
  RCC_PeriphCLKInitTypeDef PeriphClkInit = {0};

  /** Configure the main internal regulator output voltage
  */
  HAL_PWREx_ControlVoltageScaling(PWR_REGULATOR_VOLTAGE_SCALE1_BOOST);
  /** Initializes the CPU, AHB and APB busses clocks
  */
  RCC_OscInitStruct.OscillatorType = RCC_OSCILLATORTYPE_HSE;
  RCC_OscInitStruct.HSEState = RCC_HSE_ON;
  RCC_OscInitStruct.PLL.PLLState = RCC_PLL_ON;
  RCC_OscInitStruct.PLL.PLLSource = RCC_PLLSOURCE_HSE;
  RCC_OscInitStruct.PLL.PLLM = RCC_PLLM_DIV2;
  RCC_OscInitStruct.PLL.PLLN = 85;
  RCC_OscInitStruct.PLL.PLLP = RCC_PLLP_DIV8;
  RCC_OscInitStruct.PLL.PLLQ = RCC_PLLQ_DIV2;
  RCC_OscInitStruct.PLL.PLLR = RCC_PLLR_DIV2;
  if (HAL_RCC_OscConfig(&RCC_OscInitStruct) != HAL_OK)
  {
    Error_Handler();
  }
  /** Initializes the CPU, AHB and APB busses clocks
  */
  RCC_ClkInitStruct.ClockType = RCC_CLOCKTYPE_HCLK|RCC_CLOCKTYPE_SYSCLK
                              |RCC_CLOCKTYPE_PCLK1|RCC_CLOCKTYPE_PCLK2;
  RCC_ClkInitStruct.SYSCLKSource = RCC_SYSCLKSOURCE_PLLCLK;
  RCC_ClkInitStruct.AHBCLKDivider = RCC_SYSCLK_DIV1;
  RCC_ClkInitStruct.APB1CLKDivider = RCC_HCLK_DIV1;
  RCC_ClkInitStruct.APB2CLKDivider = RCC_HCLK_DIV1;

  if (HAL_RCC_ClockConfig(&RCC_ClkInitStruct, FLASH_LATENCY_8) != HAL_OK)
  {
    Error_Handler();
  }
  /** Initializes the peripherals clocks
  */
  PeriphClkInit.PeriphClockSelection = RCC_PERIPHCLK_USART1|RCC_PERIPHCLK_ADC12;
  PeriphClkInit.Usart1ClockSelection = RCC_USART1CLKSOURCE_PCLK2;
  PeriphClkInit.Adc12ClockSelection = RCC_ADC12CLKSOURCE_PLL;
  if (HAL_RCCEx_PeriphCLKConfig(&PeriphClkInit) != HAL_OK)
  {
    Error_Handler();
  }
}

/**
  * @brief NVIC Configuration.
  * @retval None
  */
static void MX_NVIC_Init(void)
{
  /* TIM1_BRK_TIM15_IRQn interrupt configuration */
  HAL_NVIC_SetPriority(TIM1_BRK_TIM15_IRQn, 4, 1);
  HAL_NVIC_EnableIRQ(TIM1_BRK_TIM15_IRQn);
  /* TIM1_UP_TIM16_IRQn interrupt configuration */
  HAL_NVIC_SetPriority(TIM1_UP_TIM16_IRQn, 0, 0);
  HAL_NVIC_EnableIRQ(TIM1_UP_TIM16_IRQn);
  /* ADC1_2_IRQn interrupt configuration */
  HAL_NVIC_SetPriority(ADC1_2_IRQn, 2, 0);
  HAL_NVIC_EnableIRQ(ADC1_2_IRQn);
  /* USART1_IRQn interrupt configuration */
  HAL_NVIC_SetPriority(USART1_IRQn, 3, 1);
  HAL_NVIC_EnableIRQ(USART1_IRQn);
  /* EXTI15_10_IRQn interrupt configuration */
  HAL_NVIC_SetPriority(EXTI15_10_IRQn, 3, 0);
  HAL_NVIC_EnableIRQ(EXTI15_10_IRQn);
}

static void MX_ADC1_Init(void)
{

  ADC_MultiModeTypeDef multimode = {0};
  ADC_InjectionConfTypeDef sConfigInjected = {0};
  ADC_ChannelConfTypeDef sConfig = {0};

  /** Common config
  */
  hadc1.Instance = ADC1;
  hadc1.Init.ClockPrescaler = ADC_CLOCK_ASYNC_DIV4;
  hadc1.Init.Resolution = ADC_RESOLUTION_12B;
  hadc1.Init.DataAlign = ADC_DATAALIGN_LEFT;
  hadc1.Init.GainCompensation = 0;
  hadc1.Init.ScanConvMode = ADC_SCAN_ENABLE;
  hadc1.Init.EOCSelection = ADC_EOC_SINGLE_CONV;
  hadc1.Init.LowPowerAutoWait = DISABLE;
  hadc1.Init.ContinuousConvMode = DISABLE;
  hadc1.Init.NbrOfConversion = 2;
  hadc1.Init.DiscontinuousConvMode = DISABLE;
  hadc1.Init.ExternalTrigConv = ADC_SOFTWARE_START;
  hadc1.Init.ExternalTrigConvEdge = ADC_EXTERNALTRIGCONVEDGE_NONE;
  hadc1.Init.DMAContinuousRequests = DISABLE;
  hadc1.Init.Overrun = ADC_OVR_DATA_PRESERVED;
  hadc1.Init.OversamplingMode = DISABLE;
  if (HAL_ADC_Init(&hadc1) != HAL_OK)
  {
    Error_Handler();
  }
  /** Configure the ADC multi-mode
  */
  multimode.Mode = ADC_MODE_INDEPENDENT;
  if (HAL_ADCEx_MultiModeConfigChannel(&hadc1, &multimode) != HAL_OK)
  {
    Error_Handler();
  }
  /** Configure Injected Channel
  */
  sConfigInjected.InjectedChannel = ADC_CHANNEL_3;
  sConfigInjected.InjectedRank = ADC_INJECTED_RANK_1;
  sConfigInjected.InjectedSamplingTime = ADC_SAMPLETIME_6CYCLES_5;
  sConfigInjected.InjectedSingleDiff = ADC_SINGLE_ENDED;
  sConfigInjected.InjectedOffsetNumber = ADC_OFFSET_NONE;
  sConfigInjected.InjectedOffset = 0;
  sConfigInjected.InjectedNbrOfConversion = 2;
  sConfigInjected.InjectedDiscontinuousConvMode = DISABLE;
  sConfigInjected.AutoInjectedConv = DISABLE;
  sConfigInjected.QueueInjectedContext = DISABLE;
  sConfigInjected.ExternalTrigInjecConv = ADC_EXTERNALTRIGINJEC_T1_CC4;
  sConfigInjected.ExternalTrigInjecConvEdge = ADC_EXTERNALTRIGINJECCONV_EDGE_RISING;
  sConfigInjected.InjecOversamplingMode = DISABLE;
  if (HAL_ADCEx_InjectedConfigChannel(&hadc1, &sConfigInjected) != HAL_OK)
  {
    Error_Handler();
  }
  /** Configure Injected Channel
  */
  sConfigInjected.InjectedChannel = ADC_CHANNEL_12;
  sConfigInjected.InjectedRank = ADC_INJECTED_RANK_2;
  if (HAL_ADCEx_InjectedConfigChannel(&hadc1, &sConfigInjected) != HAL_OK)
  {
    Error_Handler();
  }
  /** Configure Regular Channel
  */
  sConfig.Channel = ADC_CHANNEL_1;
  sConfig.Rank = ADC_REGULAR_RANK_1;
  sConfig.SamplingTime = ADC_SAMPLETIME_47CYCLES_5;
  sConfig.SingleDiff = ADC_SINGLE_ENDED;
  sConfig.OffsetNumber = ADC_OFFSET_NONE;
  sConfig.Offset = 0;
  if (HAL_ADC_ConfigChannel(&hadc1, &sConfig) != HAL_OK)
  {
    Error_Handler();
  }
  /** Configure Regular Channel
  */
  sConfig.Channel = ADC_CHANNEL_5;
  sConfig.Rank = ADC_REGULAR_RANK_2;
  if (HAL_ADC_ConfigChannel(&hadc1, &sConfig) != HAL_OK)
  {
    Error_Handler();
  }

}

static void MX_ADC2_Init(void)
{

  ADC_InjectionConfTypeDef sConfigInjected = {0};

  /** Common config
  */
  hadc2.Instance = ADC2;
  hadc2.Init.ClockPrescaler = ADC_CLOCK_ASYNC_DIV4;
  hadc2.Init.Resolution = ADC_RESOLUTION_12B;
  hadc2.Init.DataAlign = ADC_DATAALIGN_LEFT;
  hadc2.Init.GainCompensation = 0;
  hadc2.Init.ScanConvMode = ADC_SCAN_ENABLE;
  hadc2.Init.EOCSelection = ADC_EOC_SINGLE_CONV;
  hadc2.Init.LowPowerAutoWait = DISABLE;
  hadc2.Init.ContinuousConvMode = DISABLE;
  hadc2.Init.NbrOfConversion = 1;
  hadc2.Init.DiscontinuousConvMode = DISABLE;
  hadc2.Init.DMAContinuousRequests = DISABLE;
  hadc2.Init.Overrun = ADC_OVR_DATA_PRESERVED;
  hadc2.Init.OversamplingMode = DISABLE;
  if (HAL_ADC_Init(&hadc2) != HAL_OK)
  {
    Error_Handler();
  }
  /** Configure Injected Channel
  */
  sConfigInjected.InjectedChannel = ADC_CHANNEL_3;
  sConfigInjected.InjectedRank = ADC_INJECTED_RANK_1;
  sConfigInjected.InjectedSamplingTime = ADC_SAMPLETIME_6CYCLES_5;
  sConfigInjected.InjectedSingleDiff = ADC_SINGLE_ENDED;
  sConfigInjected.InjectedOffsetNumber = ADC_OFFSET_NONE;
  sConfigInjected.InjectedOffset = 0;
  sConfigInjected.InjectedNbrOfConversion = 2;
  sConfigInjected.InjectedDiscontinuousConvMode = DISABLE;
  sConfigInjected.AutoInjectedConv = DISABLE;
  sConfigInjected.QueueInjectedContext = DISABLE;
  sConfigInjected.ExternalTrigInjecConv = ADC_EXTERNALTRIGINJEC_T1_CC4;
  sConfigInjected.ExternalTrigInjecConvEdge = ADC_EXTERNALTRIGINJECCONV_EDGE_RISING;
  sConfigInjected.InjecOversamplingMode = DISABLE;
  if (HAL_ADCEx_InjectedConfigChannel(&hadc2, &sConfigInjected) != HAL_OK)
  {
    Error_Handler();
  }
  /** Configure Injected Channel
  */
  sConfigInjected.InjectedChannel = ADC_CHANNEL_VOPAMP3_ADC2;
  sConfigInjected.InjectedRank = ADC_INJECTED_RANK_2;
  if (HAL_ADCEx_InjectedConfigChannel(&hadc2, &sConfigInjected) != HAL_OK)
  {
    Error_Handler();
  }

}

static void MX_COMP1_Init(void)
{

  hcomp1.Instance = COMP1;
  hcomp1.Init.InputPlus = COMP_INPUT_PLUS_IO1;
  hcomp1.Init.InputMinus = COMP_INPUT_MINUS_1_4VREFINT;
  hcomp1.Init.OutputPol = COMP_OUTPUTPOL_NONINVERTED;
  hcomp1.Init.Hysteresis = COMP_HYSTERESIS_NONE;
  hcomp1.Init.BlankingSrce = COMP_BLANKINGSRC_NONE;
  hcomp1.Init.TriggerMode = COMP_TRIGGERMODE_NONE;
  if (HAL_COMP_Init(&hcomp1) != HAL_OK)
  {
    Error_Handler();
  }

}

static void MX_COMP2_Init(void)
{

  hcomp2.Instance = COMP2;
  hcomp2.Init.InputPlus = COMP_INPUT_PLUS_IO1;
  hcomp2.Init.InputMinus = COMP_INPUT_MINUS_1_4VREFINT;
  hcomp2.Init.OutputPol = COMP_OUTPUTPOL_NONINVERTED;
  hcomp2.Init.Hysteresis = COMP_HYSTERESIS_NONE;
  hcomp2.Init.BlankingSrce = COMP_BLANKINGSRC_NONE;
  hcomp2.Init.TriggerMode = COMP_TRIGGERMODE_NONE;
  if (HAL_COMP_Init(&hcomp2) != HAL_OK)
  {
    Error_Handler();
  }

}

static void MX_COMP4_Init(void)
{

  hcomp4.Instance = COMP4;
  hcomp4.Init.InputPlus = COMP_INPUT_PLUS_IO1;
  hcomp4.Init.InputMinus = COMP_INPUT_MINUS_1_4VREFINT;
  hcomp4.Init.OutputPol = COMP_OUTPUTPOL_NONINVERTED;
  hcomp4.Init.Hysteresis = COMP_HYSTERESIS_NONE;
  hcomp4.Init.BlankingSrce = COMP_BLANKINGSRC_NONE;
  hcomp4.Init.TriggerMode = COMP_TRIGGERMODE_NONE;
  if (HAL_COMP_Init(&hcomp4) != HAL_OK)
  {
    Error_Handler();
  }

}

static void MX_CORDIC_Init(void)
{

  hcordic.Instance = CORDIC;
  if (HAL_CORDIC_Init(&hcordic) != HAL_OK)
  {
    Error_Handler();
  }

}

static void MX_DAC1_Init(void)
{

  DAC_ChannelConfTypeDef sConfig = {0};

  /** DAC Initialization
  */
  hdac1.Instance = DAC1;
  if (HAL_DAC_Init(&hdac1) != HAL_OK)
  {
    Error_Handler();
  }
  /** DAC channel OUT1 config
  */
  sConfig.DAC_HighFrequency = DAC_HIGH_FREQUENCY_INTERFACE_MODE_AUTOMATIC;
  sConfig.DAC_DMADoubleDataMode = DISABLE;
  sConfig.DAC_SignedFormat = DISABLE;
  sConfig.DAC_SampleAndHold = DAC_SAMPLEANDHOLD_DISABLE;
  sConfig.DAC_Trigger = DAC_TRIGGER_SOFTWARE;
  sConfig.DAC_Trigger2 = DAC_TRIGGER_NONE;
  sConfig.DAC_OutputBuffer = DAC_OUTPUTBUFFER_DISABLE;
  sConfig.DAC_ConnectOnChipPeripheral = DAC_CHIPCONNECT_DISABLE;
  sConfig.DAC_UserTrimming = DAC_TRIMMING_FACTORY;
  if (HAL_DAC_ConfigChannel(&hdac1, &sConfig, DAC_CHANNEL_1) != HAL_OK)
  {
    Error_Handler();
  }

}

static void MX_OPAMP1_Init(void)
{

  hopamp1.Instance = OPAMP1;
  hopamp1.Init.PowerMode = OPAMP_POWERMODE_NORMAL;
  hopamp1.Init.Mode = OPAMP_PGA_MODE;
  hopamp1.Init.NonInvertingInput = OPAMP_NONINVERTINGINPUT_IO0;
  hopamp1.Init.InternalOutput = DISABLE;
  hopamp1.Init.TimerControlledMuxmode = OPAMP_TIMERCONTROLLEDMUXMODE_DISABLE;
  hopamp1.Init.PgaConnect = OPAMP_PGA_CONNECT_INVERTINGINPUT_IO0_BIAS;
  hopamp1.Init.PgaGain = OPAMP_PGA_GAIN_16_OR_MINUS_15;
  hopamp1.Init.UserTrimming = OPAMP_TRIMMING_FACTORY;
  if (HAL_OPAMP_Init(&hopamp1) != HAL_OK)
  {
    Error_Handler();
  }

}

static void MX_OPAMP2_Init(void)
{

  hopamp2.Instance = OPAMP2;
  hopamp2.Init.PowerMode = OPAMP_POWERMODE_NORMAL;
  hopamp2.Init.Mode = OPAMP_PGA_MODE;
  hopamp2.Init.NonInvertingInput = OPAMP_NONINVERTINGINPUT_IO0;
  hopamp2.Init.InternalOutput = DISABLE;
  hopamp2.Init.TimerControlledMuxmode = OPAMP_TIMERCONTROLLEDMUXMODE_DISABLE;
  hopamp2.Init.PgaConnect = OPAMP_PGA_CONNECT_INVERTINGINPUT_IO0_BIAS;
  hopamp2.Init.PgaGain = OPAMP_PGA_GAIN_16_OR_MINUS_15;
  hopamp2.Init.UserTrimming = OPAMP_TRIMMING_FACTORY;
  if (HAL_OPAMP_Init(&hopamp2) != HAL_OK)
  {
    Error_Handler();
  }

}

static void MX_OPAMP3_Init(void)
{

  hopamp3.Instance = OPAMP3;
  hopamp3.Init.PowerMode = OPAMP_POWERMODE_NORMAL;
  hopamp3.Init.Mode = OPAMP_PGA_MODE;
  hopamp3.Init.NonInvertingInput = OPAMP_NONINVERTINGINPUT_IO0;
  hopamp3.Init.InternalOutput = ENABLE;
  hopamp3.Init.TimerControlledMuxmode = OPAMP_TIMERCONTROLLEDMUXMODE_DISABLE;
  hopamp3.Init.PgaConnect = OPAMP_PGA_CONNECT_INVERTINGINPUT_IO0_BIAS;
  hopamp3.Init.PgaGain = OPAMP_PGA_GAIN_16_OR_MINUS_15;
  hopamp3.Init.UserTrimming = OPAMP_TRIMMING_FACTORY;
  if (HAL_OPAMP_Init(&hopamp3) != HAL_OK)
  {
    Error_Handler();
  }

}

static void MX_SPI1_Init(void)
{

  /* SPI1 parameter configuration*/
  hspi1.Instance = SPI1;
  hspi1.Init.Mode = SPI_MODE_MASTER;
  hspi1.Init.Direction = SPI_DIRECTION_2LINES;
  hspi1.Init.DataSize = SPI_DATASIZE_16BIT;
  hspi1.Init.CLKPolarity = SPI_POLARITY_LOW;
  hspi1.Init.CLKPhase = SPI_PHASE_1EDGE;
  hspi1.Init.NSS = SPI_NSS_HARD_OUTPUT;
  hspi1.Init.BaudRatePrescaler = SPI_BAUDRATEPRESCALER_32;
  hspi1.Init.FirstBit = SPI_FIRSTBIT_MSB;
  hspi1.Init.TIMode = SPI_TIMODE_DISABLE;
  hspi1.Init.CRCCalculation = SPI_CRCCALCULATION_DISABLE;
  hspi1.Init.CRCPolynomial = 7;
  hspi1.Init.CRCLength = SPI_CRC_LENGTH_DATASIZE;
  hspi1.Init.NSSPMode = SPI_NSS_PULSE_ENABLE;
  if (HAL_SPI_Init(&hspi1) != HAL_OK)
  {
    Error_Handler();
  }
  /* USER CODE BEGIN SPI1_Init 2 */
  __HAL_SPI_ENABLE(&hspi1);
  /* USER CODE END SPI1_Init 2 */

}

static void MX_TIM1_Init(void)
{

  TIM_SlaveConfigTypeDef sSlaveConfig = {0};
  TIM_MasterConfigTypeDef sMasterConfig = {0};
  TIMEx_BreakInputConfigTypeDef sBreakInputConfig = {0};
  TIM_OC_InitTypeDef sConfigOC = {0};
  TIM_BreakDeadTimeConfigTypeDef sBreakDeadTimeConfig = {0};

  htim1.Instance = TIM1;
  htim1.Init.Prescaler = ((TIM_CLOCK_DIVIDER) - 1);
  htim1.Init.CounterMode = TIM_COUNTERMODE_CENTERALIGNED1;
  htim1.Init.Period = ((PWM_PERIOD_CYCLES) / 2);
  htim1.Init.ClockDivision = TIM_CLOCKDIVISION_DIV2;
  htim1.Init.RepetitionCounter = (REP_COUNTER);
  htim1.Init.AutoReloadPreload = TIM_AUTORELOAD_PRELOAD_DISABLE;
  if (HAL_TIM_Base_Init(&htim1) != HAL_OK)
  {
    Error_Handler();
  }
  if (HAL_TIM_PWM_Init(&htim1) != HAL_OK)
  {
    Error_Handler();
  }
  sSlaveConfig.SlaveMode = TIM_SLAVEMODE_TRIGGER;
  sSlaveConfig.InputTrigger = TIM_TS_ITR1;
  if (HAL_TIM_SlaveConfigSynchro(&htim1, &sSlaveConfig) != HAL_OK)
  {
    Error_Handler();
  }
  sMasterConfig.MasterOutputTrigger = TIM_TRGO_OC4REF;
  sMasterConfig.MasterOutputTrigger2 = TIM_TRGO2_RESET;
  sMasterConfig.MasterSlaveMode = TIM_MASTERSLAVEMODE_DISABLE;
  if (HAL_TIMEx_MasterConfigSynchronization(&htim1, &sMasterConfig) != HAL_OK)
  {
    Error_Handler();
  }
  sBreakInputConfig.Source = TIM_BREAKINPUTSOURCE_COMP1;
  sBreakInputConfig.Enable = TIM_BREAKINPUTSOURCE_ENABLE;
  sBreakInputConfig.Polarity = TIM_BREAKINPUTSOURCE_POLARITY_HIGH;
  if (HAL_TIMEx_ConfigBreakInput(&htim1, TIM_BREAKINPUT_BRK2, &sBreakInputConfig) != HAL_OK)
  {
    Error_Handler();
  }
  sBreakInputConfig.Source = TIM_BREAKINPUTSOURCE_COMP2;
  if (HAL_TIMEx_ConfigBreakInput(&htim1, TIM_BREAKINPUT_BRK2, &sBreakInputConfig) != HAL_OK)
  {
    Error_Handler();
  }
  sBreakInputConfig.Source = TIM_BREAKINPUTSOURCE_COMP4;
  if (HAL_TIMEx_ConfigBreakInput(&htim1, TIM_BREAKINPUT_BRK2, &sBreakInputConfig) != HAL_OK)
  {
    Error_Handler();
  }
  sConfigOC.OCMode = TIM_OCMODE_PWM1;
  sConfigOC.Pulse = 0;
  sConfigOC.OCPolarity = TIM_OCPOLARITY_HIGH;
  sConfigOC.OCNPolarity = TIM_OCNPOLARITY_HIGH;
  sConfigOC.OCFastMode = TIM_OCFAST_DISABLE;
  sConfigOC.OCIdleState = TIM_OCIDLESTATE_RESET;
  sConfigOC.OCNIdleState = TIM_OCNIDLESTATE_RESET;
  if (HAL_TIM_PWM_ConfigChannel(&htim1, &sConfigOC, TIM_CHANNEL_1) != HAL_OK)
  {
    Error_Handler();
  }
  sConfigOC.Pulse = 0;
  if (HAL_TIM_PWM_ConfigChannel(&htim1, &sConfigOC, TIM_CHANNEL_2) != HAL_OK)
  {
    Error_Handler();
  }
  sConfigOC.Pulse = 0;
  if (HAL_TIM_PWM_ConfigChannel(&htim1, &sConfigOC, TIM_CHANNEL_3) != HAL_OK)
  {
    Error_Handler();
  }
  sConfigOC.OCMode = TIM_OCMODE_PWM2;
  sConfigOC.Pulse = 0;
  sConfigOC.OCNPolarity = TIM_OCNPOLARITY_HIGH;
  if (HAL_TIM_PWM_ConfigChannel(&htim1, &sConfigOC, TIM_CHANNEL_4) != HAL_OK)
  {
    Error_Handler();
  }
  sBreakDeadTimeConfig.OffStateRunMode = TIM_OSSR_ENABLE;
  sBreakDeadTimeConfig.OffStateIDLEMode = TIM_OSSI_ENABLE;
  sBreakDeadTimeConfig.LockLevel = TIM_LOCKLEVEL_1;
  sBreakDeadTimeConfig.DeadTime = ((DEAD_TIME_COUNTS) / 2);
  sBreakDeadTimeConfig.BreakState = TIM_BREAK_DISABLE;
  sBreakDeadTimeConfig.BreakPolarity = TIM_BREAKPOLARITY_HIGH;
  sBreakDeadTimeConfig.BreakFilter = 0;
  sBreakDeadTimeConfig.BreakAFMode = TIM_BREAK_AFMODE_INPUT;
  sBreakDeadTimeConfig.Break2State = TIM_BREAK2_ENABLE;
  sBreakDeadTimeConfig.Break2Polarity = TIM_BREAK2POLARITY_HIGH;
  sBreakDeadTimeConfig.Break2Filter = 3;
  sBreakDeadTimeConfig.Break2AFMode = TIM_BREAK_AFMODE_INPUT;
  sBreakDeadTimeConfig.AutomaticOutput = TIM_AUTOMATICOUTPUT_DISABLE;
  if (HAL_TIMEx_ConfigBreakDeadTime(&htim1, &sBreakDeadTimeConfig) != HAL_OK)
  {
    Error_Handler();
  }
  HAL_TIM_MspPostInit(&htim1);

}

static void MX_USART1_UART_Init(void)
{

  huart1.Instance = USART1;
  huart1.Init.BaudRate = 115200;
  huart1.Init.WordLength = UART_WORDLENGTH_8B;
  huart1.Init.StopBits = UART_STOPBITS_1;
  huart1.Init.Parity = UART_PARITY_NONE;
  huart1.Init.Mode = UART_MODE_TX_RX;
  huart1.Init.HwFlowCtl = UART_HWCONTROL_NONE;
  huart1.Init.OverSampling = UART_OVERSAMPLING_16;
  huart1.Init.OneBitSampling = UART_ONE_BIT_SAMPLE_DISABLE;
  huart1.Init.ClockPrescaler = UART_PRESCALER_DIV1;
  huart1.AdvancedInit.AdvFeatureInit = UART_ADVFEATURE_NO_INIT;
  if (HAL_UART_Init(&huart1) != HAL_OK)
  {
    Error_Handler();
  }
  if (HAL_UARTEx_SetTxFifoThreshold(&huart1, UART_TXFIFO_THRESHOLD_1_8) != HAL_OK)
  {
    Error_Handler();
  }
  if (HAL_UARTEx_SetRxFifoThreshold(&huart1, UART_RXFIFO_THRESHOLD_1_8) != HAL_OK)
  {
    Error_Handler();
  }
  if (HAL_UARTEx_DisableFifoMode(&huart1) != HAL_OK)
  {
    Error_Handler();
  }

}

static void MX_GPIO_Init(void)
{
  GPIO_InitTypeDef GPIO_InitStruct = {0};

  /* GPIO Ports Clock Enable */
  __HAL_RCC_GPIOC_CLK_ENABLE();
  __HAL_RCC_GPIOF_CLK_ENABLE();
  __HAL_RCC_GPIOA_CLK_ENABLE();
  __HAL_RCC_GPIOB_CLK_ENABLE();

  /*Configure GPIO pin : Start_Stop_Pin */
  GPIO_InitStruct.Pin = Start_Stop_Pin;
  GPIO_InitStruct.Mode = GPIO_MODE_IT_FALLING;
  GPIO_InitStruct.Pull = GPIO_NOPULL;
  HAL_GPIO_Init(Start_Stop_GPIO_Port, &GPIO_InitStruct);

}

void Error_Handler(void)
{
}

/************************ (C) COPYRIGHT STMicroelectronics *****END OF FILE****/
